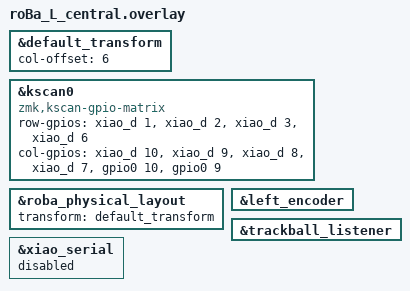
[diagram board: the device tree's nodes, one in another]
#include "roBa.dtsi"
#include "roBa_trackball.dtsi"



&default_transform {
     col-offset = <6>;
 };
 
&kscan0 {
  compatible = "zmk,kscan-gpio-matrix";
     row-gpios
        = <&xiao_d 1 (GPIO_ACTIVE_HIGH | GPIO_PULL_DOWN)> 
        , <&xiao_d 2 (GPIO_ACTIVE_HIGH | GPIO_PULL_DOWN)> 
        , <&xiao_d 3 (GPIO_ACTIVE_HIGH | GPIO_PULL_DOWN)> 
        , <&xiao_d 6 (GPIO_ACTIVE_HIGH | GPIO_PULL_DOWN)> 			
        ;

     col-gpios
        col-gpios
        = <&xiao_d 10 GPIO_ACTIVE_HIGH>
        , <&xiao_d 9 GPIO_ACTIVE_HIGH> 
        , <&xiao_d 8 GPIO_ACTIVE_HIGH> 
        , <&xiao_d 7 GPIO_ACTIVE_HIGH> 
        , <&gpio0 10 GPIO_ACTIVE_HIGH>
        , <&gpio0 9 GPIO_ACTIVE_HIGH>
        ;
};

 &roba_physical_layout {
     transform = <&default_transform>;
 };


&left_encoder {
    status = "okay";
};


&trackball_listener {
    status = "okay";
   };

&xiao_serial { status = "disabled"; };

